# PY32F033xx register map
Vendor: Puya; Series: PY32F0; File version: 1.0.0
CPU: CM0+ r0p1, little endian, no MPU, no FPU, 4 interrupt priority bits
Registers are 32-bit, read-write, reset 0x0 unless marked. A register's access mark holds for its fields unless they carry their own. Offsets are from the block's base; [hi:lo] are bit positions; {n}, {i} and the like mark numbered series.

## TIM1 — Advanced timer
Base 0x40012C00
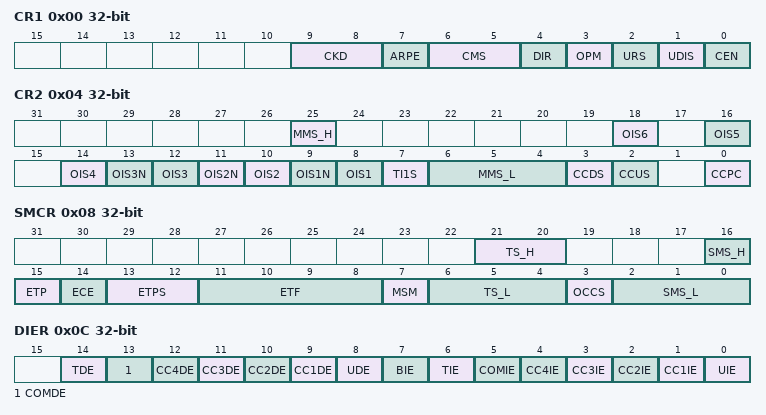
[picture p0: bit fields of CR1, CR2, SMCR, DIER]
0x00 CR1 — control register 1
  [9:8] CKD, [7] ARPE, [6:5] CMS, [4] DIR, [3] OPM, [2] URS, [1] UDIS, [0] CEN
0x04 CR2 — control register 2
  [25] MMS_H, [2n+6] OIS{n} (n=1..6), [13] OIS3N, [11] OIS2N, [9] OIS1N, [7] TI1S, [6:4] MMS_L, [3] CCDS, [2] CCUS, [0] CCPC
0x08 SMCR — slave mode control register
  [21:20] TS_H, [16] SMS_H, [15] ETP, [14] ECE, [13:12] ETPS, [11:8] ETF, [7] MSM, [6:4] TS_L, [3] OCCS, [2:0] SMS_L
0x0C DIER — DMA/Interrupt enable register
  [14] TDE, [13] COMDE, [n+8] CC{n}DE (n=1..4), [8] UDE, [7] BIE, [6] TIE, [5] COMIE, [n] CC{n}IE (n=1..4), [0] UIE
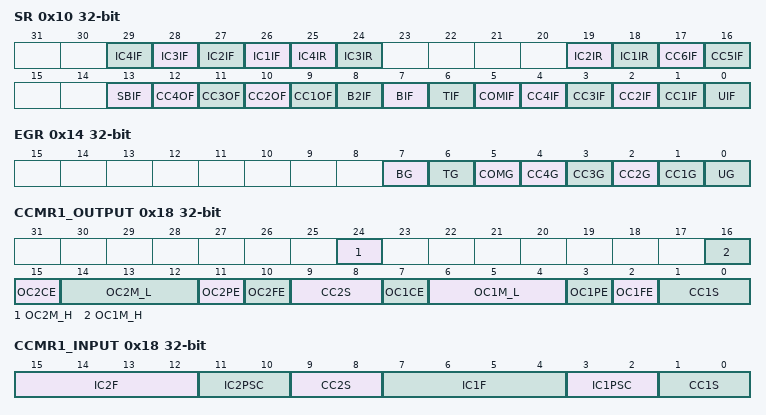
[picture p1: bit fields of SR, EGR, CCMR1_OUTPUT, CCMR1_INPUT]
0x10 SR — status register
  [n+25] IC{n}IF (n=1..4), [25] IC4IR, [24] IC3IR, [19] IC2IR, [18] IC1IR, [17] CC6IF, [16] CC5IF, [13] SBIF, [n+8] CC{n}OF (n=1..4), [8] B2IF, [7] BIF, [6] TIF, [5] COMIF, [n] CC{n}IF (n=1..4), [0] UIF
0x14 EGR — event generation register
  [7] BG, [6] TG, [5] COMG, [n] CC{n}G (n=1..4), [0] UG
0x18 CCMR1_OUTPUT
  [24] OC2M_H, [16] OC1M_H, [15] OC2CE, [14:12] OC2M_L, [11] OC2PE, [10] OC2FE, [9:8] CC2S, [7] OC1CE, [6:4] OC1M_L, [3] OC1PE, [2] OC1FE, [1:0] CC1S
0x18 CCMR1_INPUT (alternate view of CCMR1_OUTPUT)
  [15:12] IC2F, [11:10] IC2PSC, [9:8] CC2S, [7:4] IC1F, [3:2] IC1PSC, [1:0] CC1S
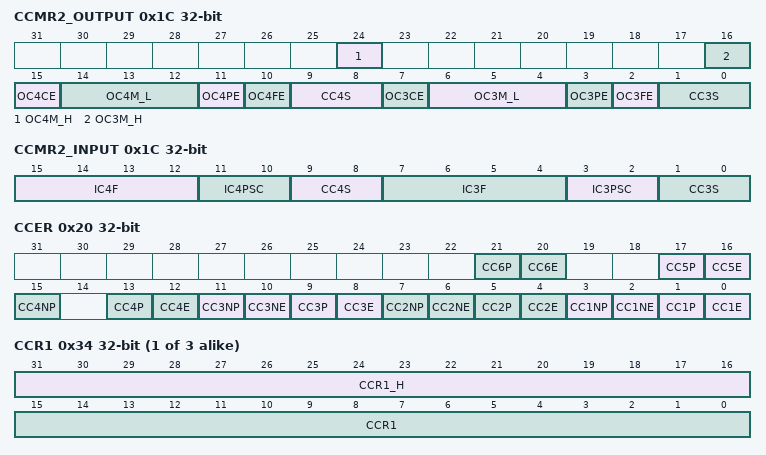
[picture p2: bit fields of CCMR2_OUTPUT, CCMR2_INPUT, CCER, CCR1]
0x1C CCMR2_OUTPUT
  [24] OC4M_H, [16] OC3M_H, [15] OC4CE, [14:12] OC4M_L, [11] OC4PE, [10] OC4FE, [9:8] CC4S, [7] OC3CE, [6:4] OC3M_L, [3] OC3PE, [2] OC3FE, [1:0] CC3S
0x1C CCMR2_INPUT (alternate view of CCMR2_OUTPUT)
  [15:12] IC4F, [11:10] IC4PSC, [9:8] CC4S, [7:4] IC3F, [3:2] IC3PSC, [1:0] CC3S
0x20 CCER — capture/compare enableregister
  [4n-3] CC{n}P (n=1..6), [4n-4] CC{n}E (n=1..6), [4n-1] CC{n}NP (n=1..4), [10] CC3NE, [6] CC2NE, [2] CC1NE
0x24 CNT — counter
  [15:0] CNT
0x28 PSC — prescaler
  [15:0] PSC
0x2C ARR — auto-reload register
  [15:0] ARR
0x30 RCR — repetition counter register
  [7:0] REP
{0x30+4i} CCR{i} (i=1..3) — capture/compare register {i}
  [31:16] CCR{i}_H, [15:0] CCR{i}
0x40 CCR4 — capture/compare register 4
  [15:0] CCR4
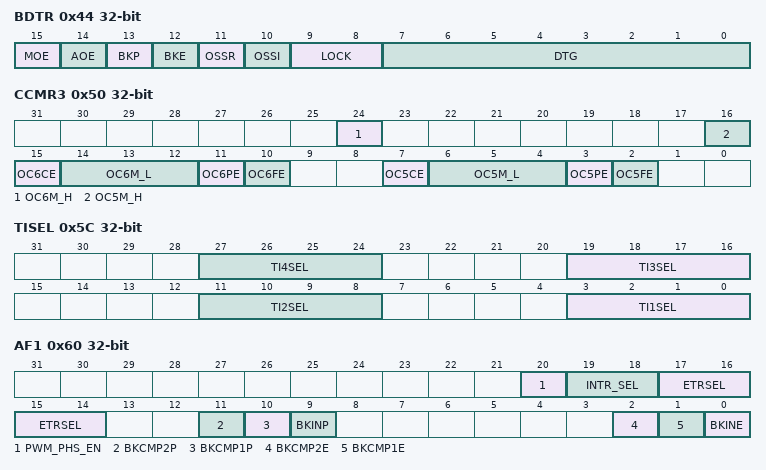
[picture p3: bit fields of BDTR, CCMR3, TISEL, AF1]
0x44 BDTR — break and dead-time register
  [15] MOE, [14] AOE, [13] BKP, [12] BKE, [11] OSSR, [10] OSSI, [9:8] LOCK, [7:0] DTG
0x48 CCR5
  [15:0] CCR5
0x4C CCR6
  [15:0] CCR6
0x50 CCMR3
  [24] OC6M_H, [16] OC5M_H, [15] OC6CE, [14:12] OC6M_L, [11] OC6PE, [10] OC6FE, [7] OC5CE, [6:4] OC5M_L, [3] OC5PE, [2] OC5FE
0x5C TISEL
  [8n-5:8n-8] TI{n}SEL (n=1..4)
0x60 AF1
  [20] PWM_PHS_EN, [19:18] INTR_SEL, [17:14] ETRSEL, [11] BKCMP2P, [10] BKCMP1P, [9] BKINP, [2] BKCMP2E, [1] BKCMP1E, [0] BKINE
0x64 AF2
  [18:16] OCRSEL
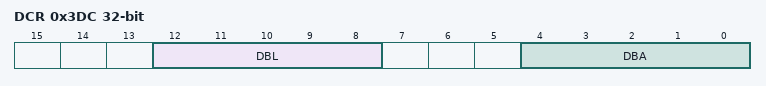
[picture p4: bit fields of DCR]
0x3DC DCR — DMA control register
  [12:8] DBL, [4:0] DBA
0x3E0 DMAR — DMA address for full transfer
  [31:0] DMAB

## TIM14 — General purpose timer
Base 0x40002000
Registers as TIM1, without CR2, SMCR, CCMR2_OUTPUT, CCMR2_INPUT, RCR, CCR{n} (n=2..6), BDTR, CCMR3, AF1, AF2, DCR, DMAR; these are added or differ:
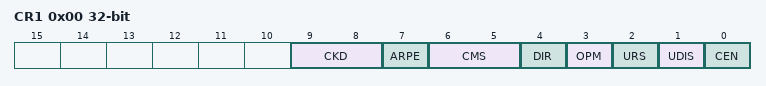
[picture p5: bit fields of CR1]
0x00 CR1 — TIM14 control register1
  [9:8] CKD, [7] ARPE, [6:5] CMS, [4] DIR, [3] OPM, [2] URS, [1] UDIS, [0] CEN
0x34 CCR1 — capture/compare register 1
  [15:0] CCR1
0x5C TISEL
  [3:0] TI1SEL

## TIM16 — General purpose timer
Base 0x40014400
Same registers: TIM17 0x40014800
Registers as TIM1, without SMCR, CCMR2_OUTPUT, CCMR2_INPUT, CCR{n} (n=2..6), CCMR3, AF2; these are added or differ:
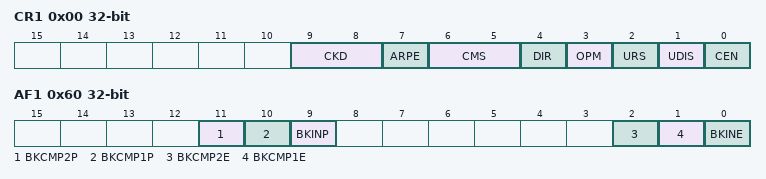
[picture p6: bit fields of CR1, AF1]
0x00 CR1 — TIM16 control register1
  [9:8] CKD, [7] ARPE, [6:5] CMS, [4] DIR, [3] OPM, [2] URS, [1] UDIS, [0] CEN
0x34 CCR1 — capture/compare register 1
  [15:0] CCR1
0x60 AF1
  [11] BKCMP2P, [10] BKCMP1P, [9] BKINP, [2] BKCMP2E, [1] BKCMP1E, [0] BKINE

## TIM3
Base 0x40000400
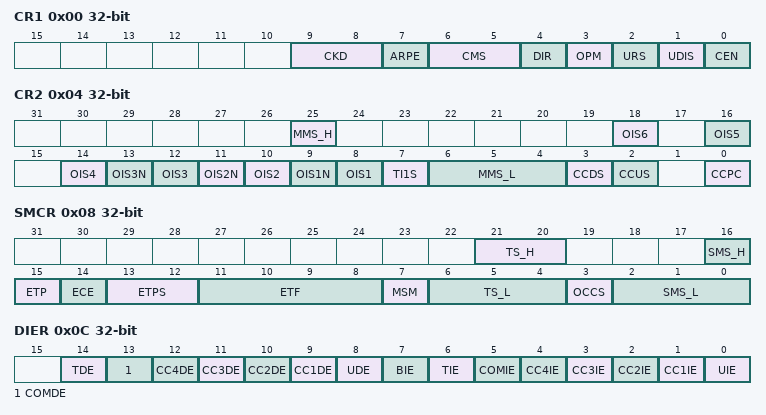
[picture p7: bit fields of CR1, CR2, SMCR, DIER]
0x00 CR1
  [9:8] CKD, [7] ARPE, [6:5] CMS, [4] DIR, [3] OPM, [2] URS, [1] UDIS, [0] CEN
0x04 CR2
  [25] MMS_H, [2n+6] OIS{n} (n=1..6), [13] OIS3N, [11] OIS2N, [9] OIS1N, [7] TI1S, [6:4] MMS_L, [3] CCDS, [2] CCUS, [0] CCPC
0x08 SMCR
  [21:20] TS_H, [16] SMS_H, [15] ETP, [14] ECE, [13:12] ETPS, [11:8] ETF, [7] MSM, [6:4] TS_L, [3] OCCS, [2:0] SMS_L
0x0C DIER
  [14] TDE, [13] COMDE, [n+8] CC{n}DE (n=1..4), [8] UDE, [7] BIE, [6] TIE, [5] COMIE, [n] CC{n}IE (n=1..4), [0] UIE
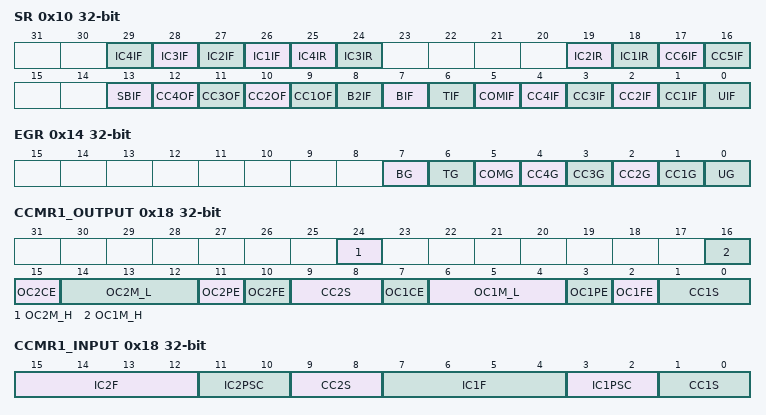
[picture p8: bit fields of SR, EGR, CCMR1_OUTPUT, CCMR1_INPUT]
0x10 SR
  [n+25] IC{n}IF (n=1..4), [25] IC4IR, [24] IC3IR, [19] IC2IR, [18] IC1IR, [17] CC6IF, [16] CC5IF, [13] SBIF, [n+8] CC{n}OF (n=1..4), [8] B2IF, [7] BIF, [6] TIF, [5] COMIF, [n] CC{n}IF (n=1..4), [0] UIF
0x14 EGR
  [7] BG, [6] TG, [5] COMG, [n] CC{n}G (n=1..4), [0] UG
0x18 CCMR1_OUTPUT
  [24] OC2M_H, [16] OC1M_H, [15] OC2CE, [14:12] OC2M_L, [11] OC2PE, [10] OC2FE, [9:8] CC2S, [7] OC1CE, [6:4] OC1M_L, [3] OC1PE, [2] OC1FE, [1:0] CC1S
0x18 CCMR1_INPUT (alternate view of CCMR1_OUTPUT)
  [15:12] IC2F, [11:10] IC2PSC, [9:8] CC2S, [7:4] IC1F, [3:2] IC1PSC, [1:0] CC1S
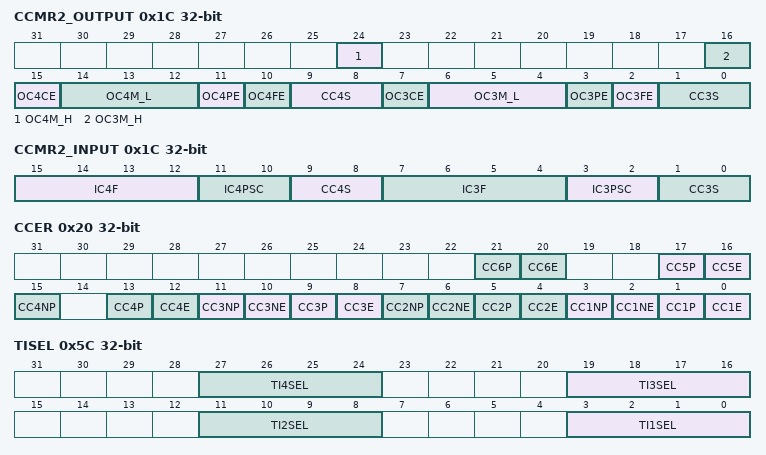
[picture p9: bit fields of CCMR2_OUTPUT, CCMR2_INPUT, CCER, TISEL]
0x1C CCMR2_OUTPUT
  [24] OC4M_H, [16] OC3M_H, [15] OC4CE, [14:12] OC4M_L, [11] OC4PE, [10] OC4FE, [9:8] CC4S, [7] OC3CE, [6:4] OC3M_L, [3] OC3PE, [2] OC3FE, [1:0] CC3S
0x1C CCMR2_INPUT (alternate view of CCMR2_OUTPUT)
  [15:12] IC4F, [11:10] IC4PSC, [9:8] CC4S, [7:4] IC3F, [3:2] IC3PSC, [1:0] CC3S
0x20 CCER
  [4n-3] CC{n}P (n=1..6), [4n-4] CC{n}E (n=1..6), [4n-1] CC{n}NP (n=1..4), [10] CC3NE, [6] CC2NE, [2] CC1NE
0x24 CNT
  [15:0] CNT
0x28 PSC
  [15:0] PSC
0x2C ARR
  [15:0] ARR
{0x30+4i} CCR{i} (i=1..4)
  [15:0] CCR{i}
0x5C TISEL
  [8n-5:8n-8] TI{n}SEL (n=1..4)
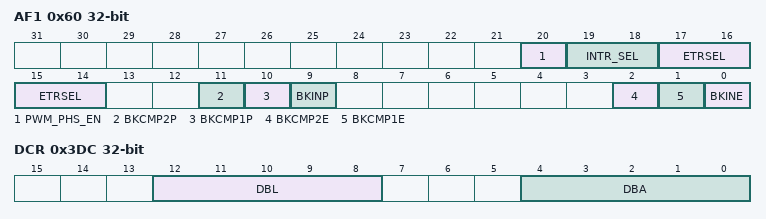
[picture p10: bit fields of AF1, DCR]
0x60 AF1
  [20] PWM_PHS_EN, [19:18] INTR_SEL, [17:14] ETRSEL, [11] BKCMP2P, [10] BKCMP1P, [9] BKINP, [2] BKCMP2E, [1] BKCMP1E, [0] BKINE
0x64 AF2
  [18:16] OCRSEL
0x3DC DCR
  [12:8] DBL, [4:0] DBA
0x3E0 DMAR
  [31:0] DMAB
